# CY8C5868AXI_LP035 register map
File version: 0.1
CY8C58LP
Registers are 8-bit, read-write, no defined reset value unless marked. A register's access mark holds for its fields unless they carry their own. Offsets are from the block's base; lines under a group give offsets from that group; [hi:lo] are bit positions; {n}, {i} and the like mark numbered series; 'fields as' and 'values as' point back to an identical list; <NAME> marks a mode.

## Memory map
0x00000000 TimerPID
0x00000000 ADC
0x00000000 pwmStepper_1
0x00000000 UART — USBFS
0x00000000 Peltier1_PWM_Ctrl
0x00000000 Peltier2_PWM_Ctrl
0x00000000 pwmFan_1
0x00000000 pwmFan_2
0x00000000 CAN_1
0x00000000 pwmStepper_2
0x40006475 Peltier_Enable
0x40006476 Peltier1_Ctrl
0x40006576 Peltier2_Ctrl

## Peltier_Enable
Base 0x40006475
0x00 Peltier_Enable_CONTROL_REG

## Peltier2_Ctrl
Base 0x40006576
Registers as Peltier_Enable (with Peltier_Enable read as Peltier2_Ctrl).

## Peltier1_Ctrl
Base 0x40006476
Registers as Peltier_Enable (with Peltier_Enable read as Peltier1_Ctrl).

## TimerPID
Base 0x00000000
0x40006504 TimerPID_COUNTER 24-bit — UDB.A0 - Current Down Counter Value
0x40006524 TimerPID_PERIOD 24-bit — UDB.D0 - Assigned Period
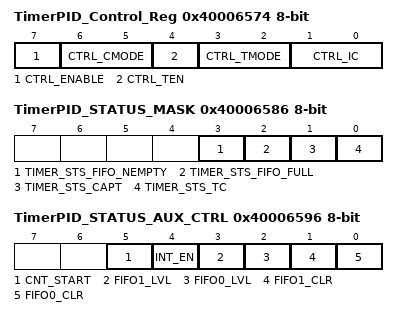
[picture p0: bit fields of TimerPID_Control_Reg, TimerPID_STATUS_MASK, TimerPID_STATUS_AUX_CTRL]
0x40006574 TimerPID_Control_Reg — UDB Control Register - Assigned Control Register Value
  [7] CTRL_ENABLE — Enable the Timer
  [6:5] CTRL_CMODE — Capture Mode
  [4] CTRL_TEN — Trigger Enable Bit
  [3:2] CTRL_TMODE — Trigger Mode
  [1:0] CTRL_IC — Interrupt Count
0x40006586 TimerPID_STATUS_MASK — UDB Status bits Interrupt Mask Enable Register
  [3] TIMER_STS_FIFO_NEMPTY ro — FIFO Empty status
  [2] TIMER_STS_FIFO_FULL ro — FIFO Full Status
  [1] TIMER_STS_CAPT ro — Enables the Interrupt on Capture
  [0] TIMER_STS_TC ro — Enables the Interrupt on TC
0x40006596 TimerPID_STATUS_AUX_CTRL — UDB Auxilliary Control Register
  [5] CNT_START — FIFO0 clear
    0=E_CNT_START0 (Disable counter); 1=E_CNT_START1 (Enable counter)
  [4] INT_EN
    0=E_INT_EN0 (Interrupt disabled); 1=E_INT_EN1 (Interrupt enabled)
  [3] FIFO1_LVL — FIFO level
    0=E_FIFO_LVL_0 (FIFO LVL: input mode: FIFO not full; output mode: FIFO not empty); 1=E_FIFO_LVL_1 (FIFO LVL: input mode: FIFO at least 1/2 empty; output mode: FIFO at least 1/2 full)
  [2] FIFO0_LVL — FIFO level
    values as FIFO1_LVL
  [1] FIFO1_CLR — FIFO1 clear
    0=E_FIFO_CLR_0 (Normal FIFO operation); 1=E_FIFO_CLR_1 (Clear FIFO state)
  [0] FIFO0_CLR — FIFO0 clear
    values as FIFO1_CLR

## pwmStepper_1
Base 0x00000000
0x40006527 pwmStepper_1_COMPARE_Reg_ — UDB.D0 - Assigned Compare Value
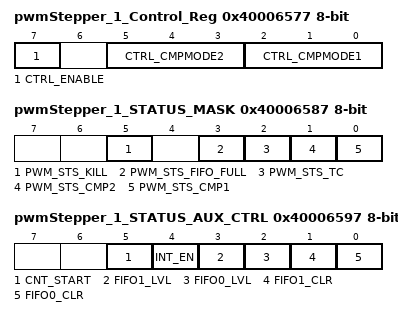
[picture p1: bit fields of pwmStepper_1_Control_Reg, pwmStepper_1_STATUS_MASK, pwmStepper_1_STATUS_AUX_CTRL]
0x40006577 pwmStepper_1_Control_Reg — UDB Control Register - Assigned Control Register Value
  [7] CTRL_ENABLE — Enable the PWM
  [5:3] CTRL_CMPMODE2 — Compare mode 2
  [2:0] CTRL_CMPMODE1 — Compare mode 1
0x40006587 pwmStepper_1_STATUS_MASK — UDB Status bits Interrupt Mask Enable Register
  [5] PWM_STS_KILL ro — Enables the Interrupt on Kill
  [3] PWM_STS_FIFO_FULL ro — FIFO Full Status Mask
  [2] PWM_STS_TC ro — Enables the Interrupt on Terminal Count
  [1] PWM_STS_CMP2 ro — Enables the Interrupt on Compare 2
  [0] PWM_STS_CMP1 ro — Enables the Interrupt on Compare 1
0x40006597 pwmStepper_1_STATUS_AUX_CTRL — UDB Auxilliary Control Register
  [5] CNT_START — FIFO0 clear
    0=E_CNT_START0 (Disable counter); 1=E_CNT_START1 (Enable counter)
  [4] INT_EN
    0=E_INT_EN0 (Interrupt disabled); 1=E_INT_EN1 (Interrupt enabled)
  [3] FIFO1_LVL — FIFO level
    0=E_FIFO_LVL_0 (FIFO LVL: input mode: FIFO not full; output mode: FIFO not empty); 1=E_FIFO_LVL_1 (FIFO LVL: input mode: FIFO at least 1/2 empty; output mode: FIFO at least 1/2 full)
  [2] FIFO0_LVL — FIFO level
    values as FIFO1_LVL
  [1] FIFO1_CLR — FIFO1 clear
    0=E_FIFO_CLR_0 (Normal FIFO operation); 1=E_FIFO_CLR_1 (Clear FIFO state)
  [0] FIFO0_CLR — FIFO0 clear
    values as FIFO1_CLR

## UART — USBFS
Base 0x00000000
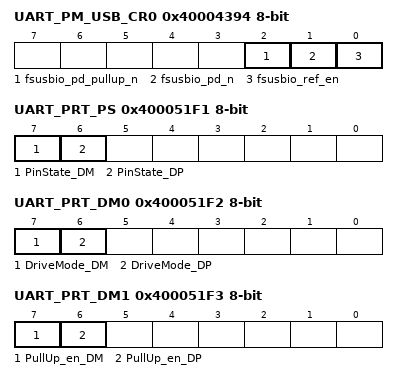
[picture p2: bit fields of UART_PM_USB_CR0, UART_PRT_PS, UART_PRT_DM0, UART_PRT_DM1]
0x40004394 UART_PM_USB_CR0 — USB Power Mode Control Register 0
  [2] fsusbio_pd_pullup_n, [1] fsusbio_pd_n, [0] fsusbio_ref_en
0x400043A5 UART_PM_ACT_CFG — Active Power Mode Configuration Register
0x400043B5 UART_PM_STBY_CFG — Standby Power Mode Configuration Register
0x400051F1 UART_PRT_PS — Port Pin State Register
  [7] PinState_DM ro, [6] PinState_DP ro
0x400051F2 UART_PRT_DM0 — Port Drive Mode Register
  [7] DriveMode_DM, [6] DriveMode_DP
0x400051F3 UART_PRT_DM1 — Port Drive Mode Register
  [7] PullUp_en_DM, [6] PullUp_en_DP
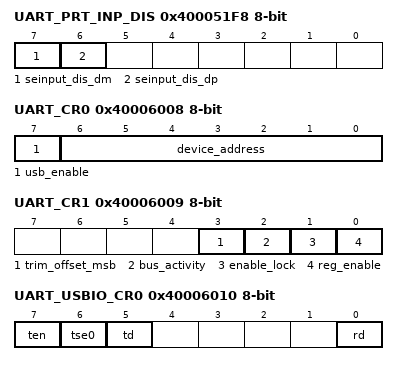
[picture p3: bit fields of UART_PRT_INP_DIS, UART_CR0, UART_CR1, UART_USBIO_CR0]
0x400051F8 UART_PRT_INP_DIS — Input buffer disable override
  [7] seinput_dis_dm, [6] seinput_dis_dp
0x40006000 UART_EP0_DR0 — bmRequestType
0x40006001 UART_EP0_DR1 — bRequest
0x40006002 UART_EP0_DR2 — wValueLo
0x40006003 UART_EP0_DR3 — wValueHi
0x40006004 UART_EP0_DR4 — wIndexLo
0x40006005 UART_EP0_DR5 — wIndexHi
0x40006006 UART_EP0_DR6 — lengthLo
0x40006007 UART_EP0_DR7 — lengthHi
0x40006008 UART_CR0 — USB Control Register 0
  [7] usb_enable, [6:0] device_address ro
0x40006009 UART_CR1 — USB Control Register 1
  [3] trim_offset_msb, [2] bus_activity, [1] enable_lock, [0] reg_enable
{0x40005FFE+0x10*i} UART_SIE_EP{i}_CR0 (i=1..8) — The Endpoint{i} Control Register
0x40006010 UART_USBIO_CR0 — USBIO Control Register 0
  [7] ten, [6] tse0, [5] td, [0] rd ro
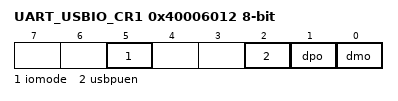
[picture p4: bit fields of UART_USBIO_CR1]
0x40006012 UART_USBIO_CR1 — USBIO Control Register 1
  [5] iomode, [2] usbpuen, [1] dpo ro, [0] dmo ro
0x4000608C UART_BUF_SIZE — Dedicated Endpoint Buffer Size Register
0x4000608E UART_EP_ACTIVE — Endpoint Active Indication Register
0x4000608F UART_EP_TYPE — Endpoint Type (IN/OUT) Indication
0x4000609D UART_USB_CLK_EN — USB Block Clock Enable Register
